# soc-dvt-2753c12 register map
Vendor: litex
Registers are 32-bit, read-write, reset 0x0 unless marked. A register's access mark holds for its fields unless they carry their own. Offsets are from the block's base; [hi:lo] are bit positions; {n}, {i} and the like mark numbered series; 'fields as' and 'values as' point back to an identical list.

## KEYBOARD
Base 0xF0017000
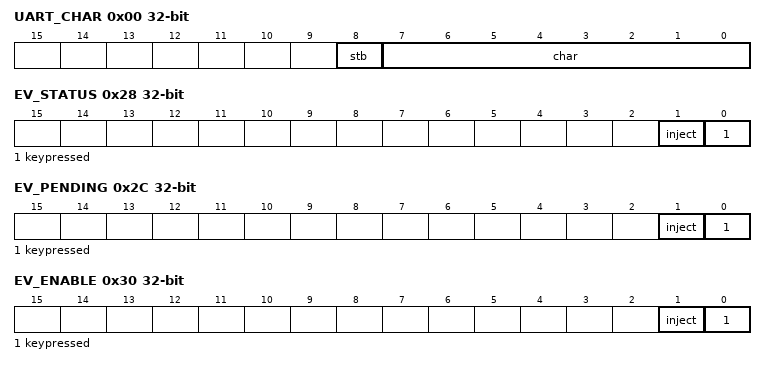
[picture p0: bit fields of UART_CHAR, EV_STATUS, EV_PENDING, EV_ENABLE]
0x00 UART_CHAR
  [8] stb — FIFO has readable characters
  [7:0] char — character value being injected
{0x4+4i} ROW{i}DAT (i=0..8) — Column data for the given row
  [9:0] row{i}dat
0x28 EV_STATUS — Key injection request received
  [1] inject — Level of the ``inject`` event
  [0] keypressed — Level of the ``keypressed`` event
0x2C EV_PENDING — Key injection request received
  [1] inject — Key injection request received
  [0] keypressed — Triggered every time there is a difference in the row state
0x30 EV_ENABLE — Key injection request received
  [1] inject — Write a ``1`` to enable the ``inject`` Event
  [0] keypressed — Write a ``1`` to enable the ``keypressed`` Event

## KEYINJECT
Base 0xF0018000
0x00 UART_CHAR
  [7:0] char — character value to inject. Automatically raises an interrupt upon write. There is no interlock or FIFO buffering on this, so you can lose characters if you inject too fast.
0x04 DISABLE
  [0] disable — writing a 1 permanently disables the block, until the next cold boot

## SEED
Base 0xF0019000
0x00 SEED1 reset 0x76D5FBEF — Bits 32-63 of `SEED_SEED`. Seed used for the build
  [31:0] seed
0x04 SEED0 reset 0x3263B756 — Bits 0-31 of `SEED_SEED`.
  [31:0] seed

## KEYROM
Base 0xF001A000
0x00 ADDRESS — address for ROM
  [7:0] address
0x04 DATA — data from ROM
0x08 LOCKADDR — address of the word to lock. Address locked on write, and cannot be undone.
  [7:0] lockaddr
0x0C LOCKSTAT — If set, the requested address word is locked and will always return 0.
  [0] lockstat

## AUDIO
Base 0xF001B000
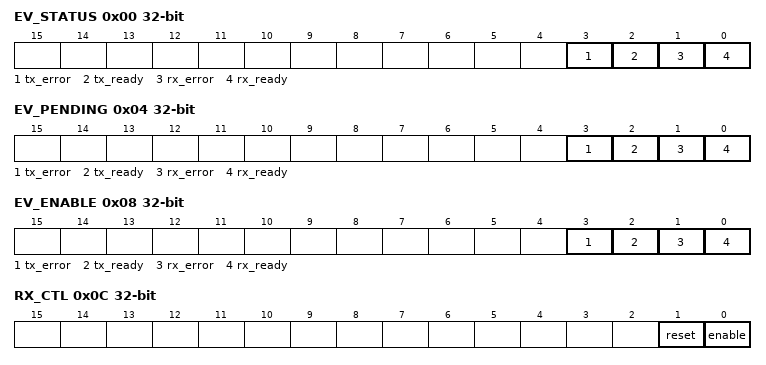
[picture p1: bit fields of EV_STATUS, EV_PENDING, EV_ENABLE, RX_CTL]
0x00 EV_STATUS — Indicates a Tx error has happened (over/underflow
  [3] tx_error — Level of the ``tx_error`` event
  [2] tx_ready — Level of the ``tx_ready`` event
  [1] rx_error — Level of the ``rx_error`` event
  [0] rx_ready — Level of the ``rx_ready`` event
0x04 EV_PENDING — Indicates a Tx error has happened (over/underflow
  [3] tx_error — Indicates a Tx error has happened (over/underflow
  [2] tx_ready — Indicates enough space available for next Tx quanta of 256 words
  [1] rx_error — Indicates an Rx error has happened (over/underflow)
  [0] rx_ready — Indicates FIFO is ready to read
0x08 EV_ENABLE — Indicates a Tx error has happened (over/underflow
  [3] tx_error — Write a ``1`` to enable the ``tx_error`` Event
  [2] tx_ready — Write a ``1`` to enable the ``tx_ready`` Event
  [1] rx_error — Write a ``1`` to enable the ``rx_error`` Event
  [0] rx_ready — Write a ``1`` to enable the ``rx_ready`` Event
0x0C RX_CTL — Rx data path control
  [1] reset — Writing `1` resets the FIFO. Reset happens regardless of enable state.
  [0] enable — Enable the receiving data
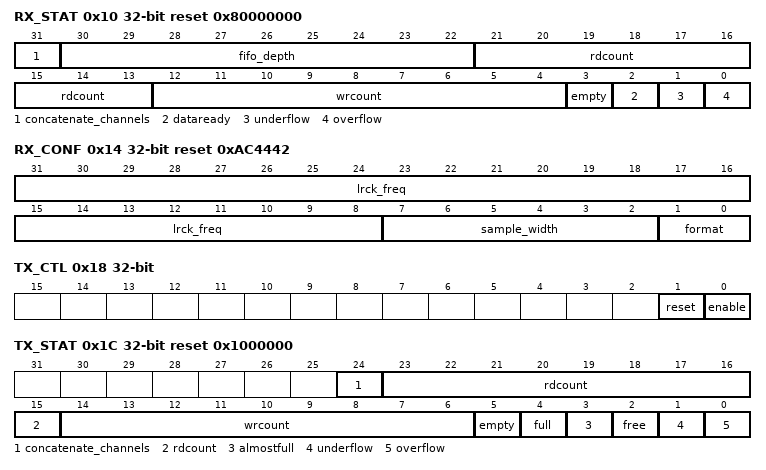
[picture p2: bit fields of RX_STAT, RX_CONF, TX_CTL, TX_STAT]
0x10 RX_STAT reset 0x80000000 — Rx data path status
  [31] concatenate_channels — Receive and send both channels atomically
  [30:22] fifo_depth — FIFO depth as synthesized
  [21:13] rdcount — Read count
  [12:4] wrcount — Write count
  [3] empty — No data available in FIFO to read
  [2] dataready — 256 words of data loaded and ready to read
  [1] underflow — Rx underflow
  [0] overflow — Rx overflow
0x14 RX_CONF reset 0xAC4442 — Rx configuration
  [31:8] lrck_freq — Audio sampling rate frequency
  [7:2] sample_width — Single sample width
  [1:0] format — I2S sample format. I2S_FORMAT.I2S_LEFT_JUSTIFIED is left-justified, I2S_FORMAT.I2S_STANDARD is I2S standard
0x18 TX_CTL — Tx data path control
  [1] reset — Writing `1` resets the FIFO. Reset happens regardless of enable state.
  [0] enable — Enable the transmission data
0x1C TX_STAT reset 0x1000000 — Tx data path status
  [24] concatenate_channels — Receive and send both channels atomically
  [23:15] rdcount — Tx read count
  [14:6] wrcount — Tx write count
  [5] empty — FIFO is empty
  [4] full — FIFO is full or overfull
  [3] almostfull — Less than 8 words space available
  [2] free — At least 256 words of space free
  [1] underflow — Tx underflow
  [0] overflow — Tx overflow
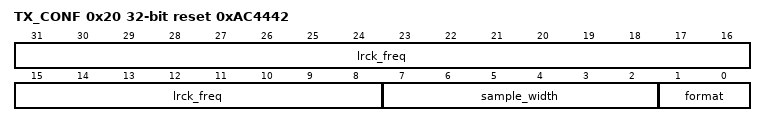
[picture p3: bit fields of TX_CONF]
0x20 TX_CONF reset 0xAC4442 — TX configuration
  fields as RX_CONF
